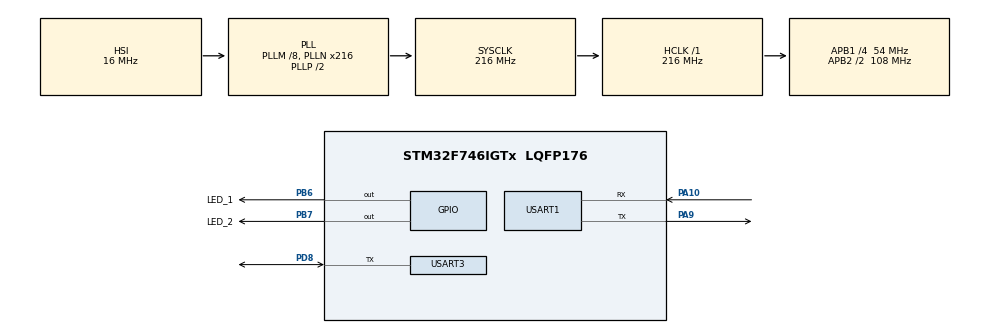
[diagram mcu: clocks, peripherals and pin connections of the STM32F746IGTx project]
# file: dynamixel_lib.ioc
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Mcu.Family=STM32F7
NVIC.USART3_IRQn=true\:0\:0\:false\:false\:true\:true\:true
Dma.USART3_RX.0.PeriphInc=DMA_PINC_DISABLE
RCC.CortexFreq_Value=216000000
Dma.USART1_TX.1.MemInc=DMA_MINC_ENABLE
PB6.GPIO_Label=LED_1
PC14/OSC32_IN.Mode=LSE-External-Oscillator
PD8.GPIO_PuPd=GPIO_PULLUP
RCC.SYSCLKSource=RCC_SYSCLKSOURCE_PLLCLK
ProjectManager.StackSize=0x400
USART3.BaudRate=57600
PH0/OSC_IN.Mode=HSE-External-Oscillator
RCC.HCLKFreq_Value=216000000
RCC.APB2TimFreq_Value=216000000
PB6.Signal=GPIO_Output
PH1/OSC_OUT.Signal=RCC_OSC_OUT
PD8.Signal=USART3_TX
RCC.AHBFreq_Value=216000000
PD8.GPIO_ModeDefaultOD=GPIO_MODE_AF_OD
RCC.HSE_VALUE=25000000
Dma.USART3_RX.0.MemDataAlignment=DMA_MDATAALIGN_BYTE
PA14.Mode=Serial_Wire
Dma.USART3_RX.0.PeriphDataAlignment=DMA_PDATAALIGN_BYTE
PB7.Signal=GPIO_Output
Dma.USART3_RX.0.FIFOMode=DMA_FIFOMODE_DISABLE
PH1/OSC_OUT.Mode=HSE-External-Oscillator
Dma.USART1_TX.1.PeriphDataAlignment=DMA_PDATAALIGN_BYTE
PB7.GPIO_Label=LED_2
Dma.USART3_RX.0.Direction=DMA_PERIPH_TO_MEMORY
Mcu.Package=LQFP176
NVIC.DMA2_Stream7_IRQn=true\:0\:0\:false\:false\:true\:false\:true
PC14/OSC32_IN.Signal=RCC_OSC32_IN
PA10.Signal=USART1_RX
Dma.USART3_RX.0.MemInc=DMA_MINC_ENABLE
RCC.APB2CLKDivider=RCC_HCLK_DIV2
Dma.Request1=USART1_TX
RCC.APB1TimFreq_Value=108000000
Dma.USART1_TX.1.Priority=DMA_PRIORITY_LOW
Dma.Request0=USART3_RX
Dma.USART1_TX.1.Direction=DMA_MEMORY_TO_PERIPH
Dma.USART3_RX.0.Instance=DMA1_Stream1
Dma.USART1_TX.1.Instance=DMA2_Stream7
PA10.Mode=Asynchronous
NVIC.DMA1_Stream1_IRQn=true\:0\:0\:false\:false\:true\:false\:true
RCC.APB1CLKDivider=RCC_HCLK_DIV4
Dma.USART3_RX.0.Mode=DMA_NORMAL
USART1.VirtualMode-Asynchronous=VM_ASYNC
PA13.Signal=SYS_JTMS-SWDIO
PA9.Mode=Asynchronous
ProjectManager.TargetToolchain=STM32CubeIDE
PA9.Signal=USART1_TX
Dma.USART1_TX.1.FIFOMode=DMA_FIFOMODE_DISABLE
RCC.USBFreq_Value=216000000
PD8.Mode=Half_duplex(single_wire_mode)
Dma.USART1_TX.1.MemDataAlignment=DMA_MDATAALIGN_BYTE
board=custom
RCC.VCOOutputFreq_Value=432000000
PH0/OSC_IN.Signal=RCC_OSC_IN
RCC.APB2Freq_Value=108000000
PA13.Mode=Serial_Wire
Mcu.Name=STM32F746IGTx
RCC.SYSCLKFreq_VALUE=216000000
Dma.USART3_RX.0.Priority=DMA_PRIORITY_HIGH
USART3.VirtualMode-Half_duplex(single_wire_mode)=VM_ASYNC
Dma.USART1_TX.1.Mode=DMA_NORMAL
PC15/OSC32_OUT.Mode=LSE-External-Oscillator
PA14.Signal=SYS_JTCK-SWCLK
ProjectManager.HeapSize=0x200
Dma.USART1_TX.1.PeriphInc=DMA_PINC_DISABLE
RCC.HSI_VALUE=16000000
PD8.GPIO_Speed=GPIO_SPEED_FREQ_HIGH
NVIC.PriorityGroup=NVIC_PRIORITYGROUP_4
RCC.PLLM=8
RCC.PLLN=216
PC15/OSC32_OUT.Signal=RCC_OSC32_OUT
RCC.APB1Freq_Value=54000000

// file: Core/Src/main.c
/* USER CODE BEGIN Header */
/**
  ******************************************************************************
  * @file           : main.c
  * @brief          : Main program body
  ******************************************************************************
  * @attention
  *
  * <h2><center>&copy; Copyright (c) 2021 STMicroelectronics.
  * All rights reserved.</center></h2>
  *
  * This software component is licensed by ST under BSD 3-Clause license,
  * the "License"; You may not use this file except in compliance with the
  * License. You may obtain a copy of the License at:
  *                        opensource.org/licenses/BSD-3-Clause
  *
  ******************************************************************************
  */
/* USER CODE END Header */
#include "main.h"

/* USER CODE BEGIN Includes */
#include "xl430.h"
#include "stdio.h"
/* USER CODE END Includes */

UART_HandleTypeDef huart1;
UART_HandleTypeDef huart3;
DMA_HandleTypeDef hdma_usart1_tx;
DMA_HandleTypeDef hdma_usart3_rx;

/* USER CODE BEGIN PV */
char debug_buffer[64];
/* USER CODE END PV */

void SystemClock_Config(void);
static void MX_GPIO_Init(void);
static void MX_DMA_Init(void);
static void MX_USART3_UART_Init(void);
static void MX_USART1_UART_Init(void);

int main(void)
{

  /* MCU Configuration--------------------------------------------------------*/

  /* Reset of all peripherals, Initializes the Flash interface and the Systick. */
  HAL_Init();

  /* Configure the system clock */
  SystemClock_Config();

  /* Initialize all configured peripherals */
  MX_GPIO_Init();
  MX_DMA_Init();
  MX_USART3_UART_Init();
  MX_USART1_UART_Init();
  /* USER CODE BEGIN 2 */

  if(xl430_debug_uart_init(&huart1) != HAL_OK)
    		  {
    			  HAL_GPIO_TogglePin(LED_1_GPIO_Port, LED_1_Pin);
    		  }

  xl430_int(&huart3);
  xl430_libTest();

  /* USER CODE END 2 */

  /* Infinite loop */
  /* USER CODE BEGIN WHILE */
  while (1)
  {
	 /* xl430_getSpeed(1);
	  xl430_getSpeed(2);
	  HAL_Delay(2000);*/

    /* USER CODE END WHILE */

  }
}

void SystemClock_Config(void)
{
  RCC_OscInitTypeDef RCC_OscInitStruct = {0};
  RCC_ClkInitTypeDef RCC_ClkInitStruct = {0};
  RCC_PeriphCLKInitTypeDef PeriphClkInitStruct = {0};

  /** Configure LSE Drive Capability
  */
  HAL_PWR_EnableBkUpAccess();
  /** Configure the main internal regulator output voltage
  */
  __HAL_RCC_PWR_CLK_ENABLE();
  __HAL_PWR_VOLTAGESCALING_CONFIG(PWR_REGULATOR_VOLTAGE_SCALE1);
  /** Initializes the RCC Oscillators according to the specified parameters
  * in the RCC_OscInitTypeDef structure.
  */
  RCC_OscInitStruct.OscillatorType = RCC_OSCILLATORTYPE_HSI;
  RCC_OscInitStruct.HSIState = RCC_HSI_ON;
  RCC_OscInitStruct.HSICalibrationValue = RCC_HSICALIBRATION_DEFAULT;
  RCC_OscInitStruct.PLL.PLLState = RCC_PLL_ON;
  RCC_OscInitStruct.PLL.PLLSource = RCC_PLLSOURCE_HSI;
  RCC_OscInitStruct.PLL.PLLM = 8;
  RCC_OscInitStruct.PLL.PLLN = 216;
  RCC_OscInitStruct.PLL.PLLP = RCC_PLLP_DIV2;
  RCC_OscInitStruct.PLL.PLLQ = 2;
  if (HAL_RCC_OscConfig(&RCC_OscInitStruct) != HAL_OK)
  {
    Error_Handler();
  }
  /** Activate the Over-Drive mode
  */
  if (HAL_PWREx_EnableOverDrive() != HAL_OK)
  {
    Error_Handler();
  }
  /** Initializes the CPU, AHB and APB buses clocks
  */
  RCC_ClkInitStruct.ClockType = RCC_CLOCKTYPE_HCLK|RCC_CLOCKTYPE_SYSCLK
                              |RCC_CLOCKTYPE_PCLK1|RCC_CLOCKTYPE_PCLK2;
  RCC_ClkInitStruct.SYSCLKSource = RCC_SYSCLKSOURCE_PLLCLK;
  RCC_ClkInitStruct.AHBCLKDivider = RCC_SYSCLK_DIV1;
  RCC_ClkInitStruct.APB1CLKDivider = RCC_HCLK_DIV4;
  RCC_ClkInitStruct.APB2CLKDivider = RCC_HCLK_DIV2;

  if (HAL_RCC_ClockConfig(&RCC_ClkInitStruct, FLASH_LATENCY_7) != HAL_OK)
  {
    Error_Handler();
  }
  PeriphClkInitStruct.PeriphClockSelection = RCC_PERIPHCLK_USART1|RCC_PERIPHCLK_USART3;
  PeriphClkInitStruct.Usart1ClockSelection = RCC_USART1CLKSOURCE_PCLK2;
  PeriphClkInitStruct.Usart3ClockSelection = RCC_USART3CLKSOURCE_PCLK1;
  if (HAL_RCCEx_PeriphCLKConfig(&PeriphClkInitStruct) != HAL_OK)
  {
    Error_Handler();
  }
}

static void MX_USART1_UART_Init(void)
{

  huart1.Instance = USART1;
  huart1.Init.BaudRate = 115200;
  huart1.Init.WordLength = UART_WORDLENGTH_8B;
  huart1.Init.StopBits = UART_STOPBITS_1;
  huart1.Init.Parity = UART_PARITY_NONE;
  huart1.Init.Mode = UART_MODE_TX_RX;
  huart1.Init.HwFlowCtl = UART_HWCONTROL_NONE;
  huart1.Init.OverSampling = UART_OVERSAMPLING_16;
  huart1.Init.OneBitSampling = UART_ONE_BIT_SAMPLE_DISABLE;
  huart1.AdvancedInit.AdvFeatureInit = UART_ADVFEATURE_NO_INIT;
  if (HAL_UART_Init(&huart1) != HAL_OK)
  {
    Error_Handler();
  }

}

static void MX_USART3_UART_Init(void)
{

  huart3.Instance = USART3;
  huart3.Init.BaudRate = 57600;
  huart3.Init.WordLength = UART_WORDLENGTH_8B;
  huart3.Init.StopBits = UART_STOPBITS_1;
  huart3.Init.Parity = UART_PARITY_NONE;
  huart3.Init.Mode = UART_MODE_TX_RX;
  huart3.Init.HwFlowCtl = UART_HWCONTROL_NONE;
  huart3.Init.OverSampling = UART_OVERSAMPLING_16;
  huart3.Init.OneBitSampling = UART_ONE_BIT_SAMPLE_DISABLE;
  huart3.AdvancedInit.AdvFeatureInit = UART_ADVFEATURE_NO_INIT;
  if (HAL_HalfDuplex_Init(&huart3) != HAL_OK)
  {
    Error_Handler();
  }

}

static void MX_DMA_Init(void)
{

  /* DMA controller clock enable */
  __HAL_RCC_DMA1_CLK_ENABLE();
  __HAL_RCC_DMA2_CLK_ENABLE();

  /* DMA interrupt init */
  /* DMA1_Stream1_IRQn interrupt configuration */
  HAL_NVIC_SetPriority(DMA1_Stream1_IRQn, 0, 0);
  HAL_NVIC_EnableIRQ(DMA1_Stream1_IRQn);
  /* DMA2_Stream7_IRQn interrupt configuration */
  HAL_NVIC_SetPriority(DMA2_Stream7_IRQn, 0, 0);
  HAL_NVIC_EnableIRQ(DMA2_Stream7_IRQn);

}

static void MX_GPIO_Init(void)
{
  GPIO_InitTypeDef GPIO_InitStruct = {0};

  /* GPIO Ports Clock Enable */
  __HAL_RCC_GPIOC_CLK_ENABLE();
  __HAL_RCC_GPIOH_CLK_ENABLE();
  __HAL_RCC_GPIOD_CLK_ENABLE();
  __HAL_RCC_GPIOA_CLK_ENABLE();
  __HAL_RCC_GPIOB_CLK_ENABLE();

  /*Configure GPIO pin Output Level */
  HAL_GPIO_WritePin(GPIOB, LED_1_Pin|LED_2_Pin, GPIO_PIN_RESET);

  /*Configure GPIO pins : LED_1_Pin LED_2_Pin */
  GPIO_InitStruct.Pin = LED_1_Pin|LED_2_Pin;
  GPIO_InitStruct.Mode = GPIO_MODE_OUTPUT_PP;
  GPIO_InitStruct.Pull = GPIO_NOPULL;
  GPIO_InitStruct.Speed = GPIO_SPEED_FREQ_LOW;
  HAL_GPIO_Init(GPIOB, &GPIO_InitStruct);

}

void Error_Handler(void)
{
  __disable_irq();
  while (1)
  {
  }
}

/************************ (C) COPYRIGHT STMicroelectronics *****END OF FILE****/
